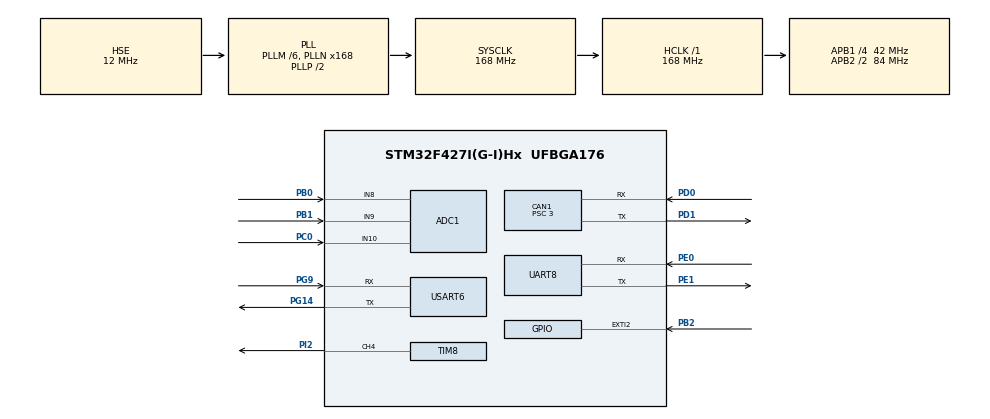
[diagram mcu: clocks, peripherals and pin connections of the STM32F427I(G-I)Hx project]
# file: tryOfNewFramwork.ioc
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ADC1.Channel-0\#ChannelRegularConversion=ADC_CHANNEL_VREFINT
ADC1.Channel-1\#ChannelRegularConversion=ADC_CHANNEL_8
ADC1.Channel-2\#ChannelRegularConversion=ADC_CHANNEL_9
ADC1.Channel-3\#ChannelRegularConversion=ADC_CHANNEL_10
ADC1.ContinuousConvMode=ENABLE
ADC1.DMAContinuousRequests=ENABLE
ADC1.NbrOfConversion=4
ADC1.NbrOfConversionFlag=1
ADC1.Rank-0\#ChannelRegularConversion=1
ADC1.Rank-1\#ChannelRegularConversion=2
ADC1.Rank-2\#ChannelRegularConversion=3
ADC1.Rank-3\#ChannelRegularConversion=4
ADC1.SamplingTime-0\#ChannelRegularConversion=ADC_SAMPLETIME_56CYCLES
ADC1.SamplingTime-1\#ChannelRegularConversion=ADC_SAMPLETIME_56CYCLES
ADC1.SamplingTime-2\#ChannelRegularConversion=ADC_SAMPLETIME_56CYCLES
ADC1.SamplingTime-3\#ChannelRegularConversion=ADC_SAMPLETIME_56CYCLES
ADC1.master=1
CAN1.BS1=CAN_BS1_9TQ
CAN1.BS2=CAN_BS2_4TQ
CAN1.CalculateTimeQuantum=71.42857142857143
CAN1.Prescaler=3
Dma.ADC1.2.Direction=DMA_PERIPH_TO_MEMORY
Dma.ADC1.2.FIFOMode=DMA_FIFOMODE_DISABLE
Dma.ADC1.2.Instance=DMA2_Stream0
Dma.ADC1.2.MemDataAlignment=DMA_MDATAALIGN_HALFWORD
Dma.ADC1.2.MemInc=DMA_MINC_ENABLE
Dma.ADC1.2.Mode=DMA_CIRCULAR
Dma.ADC1.2.PeriphDataAlignment=DMA_PDATAALIGN_HALFWORD
Dma.ADC1.2.PeriphInc=DMA_PINC_DISABLE
Dma.ADC1.2.Priority=DMA_PRIORITY_LOW
Dma.Request0=USART6_RX
Dma.Request1=USART6_TX
Dma.Request2=ADC1
Dma.Request3=UART8_RX
Dma.Request4=UART8_TX
Dma.UART8_RX.3.Direction=DMA_PERIPH_TO_MEMORY
Dma.UART8_RX.3.FIFOMode=DMA_FIFOMODE_DISABLE
Dma.UART8_RX.3.Instance=DMA1_Stream6
Dma.UART8_RX.3.MemDataAlignment=DMA_MDATAALIGN_BYTE
Dma.UART8_RX.3.MemInc=DMA_MINC_ENABLE
Dma.UART8_RX.3.Mode=DMA_NORMAL
Dma.UART8_RX.3.PeriphDataAlignment=DMA_PDATAALIGN_BYTE
Dma.UART8_RX.3.PeriphInc=DMA_PINC_DISABLE
Dma.UART8_RX.3.Priority=DMA_PRIORITY_LOW
Dma.UART8_TX.4.Direction=DMA_MEMORY_TO_PERIPH
Dma.UART8_TX.4.FIFOMode=DMA_FIFOMODE_DISABLE
Dma.UART8_TX.4.Instance=DMA1_Stream0
Dma.UART8_TX.4.MemDataAlignment=DMA_MDATAALIGN_BYTE
Dma.UART8_TX.4.MemInc=DMA_MINC_ENABLE
Dma.UART8_TX.4.Mode=DMA_NORMAL
Dma.UART8_TX.4.PeriphDataAlignment=DMA_PDATAALIGN_BYTE
Dma.UART8_TX.4.PeriphInc=DMA_PINC_DISABLE
Dma.UART8_TX.4.Priority=DMA_PRIORITY_LOW
Dma.USART6_RX.0.Direction=DMA_PERIPH_TO_MEMORY
Dma.USART6_RX.0.FIFOMode=DMA_FIFOMODE_DISABLE
Dma.USART6_RX.0.Instance=DMA2_Stream1
Dma.USART6_RX.0.MemDataAlignment=DMA_MDATAALIGN_BYTE
Dma.USART6_RX.0.MemInc=DMA_MINC_ENABLE
Dma.USART6_RX.0.Mode=DMA_NORMAL
Dma.USART6_RX.0.PeriphDataAlignment=DMA_PDATAALIGN_BYTE
Dma.USART6_RX.0.PeriphInc=DMA_PINC_DISABLE
Dma.USART6_RX.0.Priority=DMA_PRIORITY_LOW
Dma.USART6_TX.1.Direction=DMA_MEMORY_TO_PERIPH
Dma.USART6_TX.1.FIFOMode=DMA_FIFOMODE_DISABLE
Dma.USART6_TX.1.Instance=DMA2_Stream6
Dma.USART6_TX.1.MemDataAlignment=DMA_MDATAALIGN_BYTE
Dma.USART6_TX.1.MemInc=DMA_MINC_ENABLE
Dma.USART6_TX.1.Mode=DMA_NORMAL
Dma.USART6_TX.1.PeriphDataAlignment=DMA_PDATAALIGN_BYTE
Dma.USART6_TX.1.PeriphInc=DMA_PINC_DISABLE
Dma.USART6_TX.1.Priority=DMA_PRIORITY_LOW
Mcu.Family=STM32F4
Mcu.Name=STM32F427I(G-I)Hx
Mcu.Package=UFBGA176
NVIC.CAN1_RX0_IRQn=true\:0\:0\:false\:false\:true\:true\:true
NVIC.CAN1_TX_IRQn=true\:0\:0\:false\:false\:true\:true\:true
NVIC.DMA1_Stream0_IRQn=true\:0\:0\:false\:false\:true\:false\:true
NVIC.DMA1_Stream6_IRQn=true\:0\:0\:false\:false\:true\:false\:true
NVIC.DMA2_Stream0_IRQn=true\:0\:0\:false\:false\:true\:false\:true
NVIC.DMA2_Stream1_IRQn=true\:0\:0\:false\:false\:true\:false\:true
NVIC.DMA2_Stream6_IRQn=true\:0\:0\:false\:false\:true\:false\:true
NVIC.EXTI2_IRQn=true\:0\:0\:false\:false\:true\:true\:true
NVIC.PriorityGroup=NVIC_PRIORITYGROUP_4
NVIC.TIM1_UP_TIM10_IRQn=true\:0\:0\:false\:false\:true\:true\:true
NVIC.TIM6_DAC_IRQn=true\:0\:0\:false\:false\:true\:true\:true
NVIC.UART8_IRQn=true\:0\:0\:false\:false\:true\:true\:true
NVIC.USART6_IRQn=true\:0\:0\:false\:false\:true\:true\:true
PB0.Signal=ADCx_IN8
PB1.Signal=ADCx_IN9
PB2/BOOT1.Signal=GPXTI2
PC0.Signal=ADCx_IN10
PD0.Mode=Master
PD0.Signal=CAN1_RX
PD1.Mode=Master
PD1.Signal=CAN1_TX
PE0.Mode=Asynchronous
PE0.Signal=UART8_RX
PE1.Mode=Asynchronous
PE1.Signal=UART8_TX
PG14.Mode=Asynchronous
PG14.Signal=USART6_TX
PG9.Mode=Asynchronous
PG9.Signal=USART6_RX
PH0/OSC_IN.Mode=HSE-External-Oscillator
PH0/OSC_IN.Signal=RCC_OSC_IN
PH1/OSC_OUT.Mode=HSE-External-Oscillator
PH1/OSC_OUT.Signal=RCC_OSC_OUT
PI2.Signal=S_TIM8_CH4
ProjectManager.HeapSize=0x200
ProjectManager.StackSize=0x400
ProjectManager.TargetToolchain=MDK-ARM V5
RCC.48MHZClocksFreq_Value=84000000
RCC.AHBFreq_Value=168000000
RCC.APB1CLKDivider=RCC_HCLK_DIV4
RCC.APB1Freq_Value=42000000
RCC.APB1TimFreq_Value=84000000
RCC.APB2CLKDivider=RCC_HCLK_DIV2
RCC.APB2Freq_Value=84000000
RCC.APB2TimFreq_Value=168000000
RCC.CortexFreq_Value=168000000
RCC.HCLKFreq_Value=168000000
RCC.HSE_VALUE=12000000
RCC.HSI_VALUE=16000000
RCC.LSE_VALUE=32768
RCC.PLLM=6
RCC.PLLN=168
RCC.PLLSourceVirtual=RCC_PLLSOURCE_HSE
RCC.SYSCLKFreq_VALUE=168000000
RCC.SYSCLKSource=RCC_SYSCLKSOURCE_PLLCLK
RCC.VCOOutputFreq_Value=336000000
SH.ADCx_IN10.0=ADC1_IN10,IN10
SH.ADCx_IN8.0=ADC1_IN8,IN8
SH.ADCx_IN9.0=ADC1_IN9,IN9
SH.S_TIM8_CH4.0=TIM8_CH4,PWM Generation4 CH4
TIM10.Period=1000
TIM10.Prescaler=84-1
TIM6.Period=42
TIM6.Prescaler=20-1
TIM8.Channel-PWM\ Generation4\ CH4=TIM_CHANNEL_4
TIM8.Period=4200
TIM8.Prescaler=4-1
UART8.VirtualMode=Asynchronous
USART6.VirtualMode=VM_ASYNC
VP_ADC1_Vref_Input.Mode=IN-Vrefint
VP_TIM10_VS_ClockSourceINT.Mode=Enable_Timer
VP_TIM6_VS_ClockSourceINT.Mode=Enable_Timer
board=custom

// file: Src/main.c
/* USER CODE BEGIN Header */
/**
  ******************************************************************************
  * @file           : main.c
  * @brief          : Main program body
  ******************************************************************************
  * @attention
  *
  * <h2><center>&copy; Copyright (c) 2019 STMicroelectronics.
  * All rights reserved.</center></h2>
  *
  * This software component is licensed by ST under BSD 3-Clause license,
  * the "License"; You may not use this file except in compliance with the
  * License. You may obtain a copy of the License at:
  *                        opensource.org/licenses/BSD-3-Clause
  *
  ******************************************************************************
  */
	/*
	********************************************************************************
	*All the ITs are used to receive data and other procedures are done in while(1)*
	********************************************************************************
	*/
/* USER CODE END Header */

#include "main.h"
#include "adc.h"
#include "can.h"
#include "dma.h"
#include "tim.h"
#include "usart.h"
#include "gpio.h"

void SystemClock_Config(void);

/* USER CODE BEGIN 0 */
motor_receive_struct motorReceive;
motor_transmit_struct motorTransmit;
judge_receive_struct judgeReceive;
judge_transmit_struct judgeTransmit;
/* USER CODE END 0 */

int main(void)
{

  /* MCU Configuration--------------------------------------------------------*/

  /* Reset of all peripherals, Initializes the Flash interface and the Systick. */
  HAL_Init();

  /* Configure the system clock */
  SystemClock_Config();

  /* Initialize all configured peripherals */
  MX_GPIO_Init();
  MX_DMA_Init();
  MX_TIM6_Init();
  MX_CAN1_Init();
  MX_TIM8_Init();
  MX_TIM10_Init();
  MX_USART6_UART_Init();
  MX_ADC1_Init();
  MX_UART8_Init();

  /* Infinite loop */
  while (1)
  {

  }
}

void SystemClock_Config(void)
{
  RCC_OscInitTypeDef RCC_OscInitStruct = {0};
  RCC_ClkInitTypeDef RCC_ClkInitStruct = {0};

  /** Configure the main internal regulator output voltage
  */
  __HAL_RCC_PWR_CLK_ENABLE();
  __HAL_PWR_VOLTAGESCALING_CONFIG(PWR_REGULATOR_VOLTAGE_SCALE1);
  /** Initializes the CPU, AHB and APB busses clocks
  */
  RCC_OscInitStruct.OscillatorType = RCC_OSCILLATORTYPE_HSE;
  RCC_OscInitStruct.HSEState = RCC_HSE_ON;
  RCC_OscInitStruct.PLL.PLLState = RCC_PLL_ON;
  RCC_OscInitStruct.PLL.PLLSource = RCC_PLLSOURCE_HSE;
  RCC_OscInitStruct.PLL.PLLM = 6;
  RCC_OscInitStruct.PLL.PLLN = 168;
  RCC_OscInitStruct.PLL.PLLP = RCC_PLLP_DIV2;
  RCC_OscInitStruct.PLL.PLLQ = 4;
  if (HAL_RCC_OscConfig(&RCC_OscInitStruct) != HAL_OK)
  {
    Error_Handler();
  }
  /** Initializes the CPU, AHB and APB busses clocks
  */
  RCC_ClkInitStruct.ClockType = RCC_CLOCKTYPE_HCLK|RCC_CLOCKTYPE_SYSCLK
                              |RCC_CLOCKTYPE_PCLK1|RCC_CLOCKTYPE_PCLK2;
  RCC_ClkInitStruct.SYSCLKSource = RCC_SYSCLKSOURCE_PLLCLK;
  RCC_ClkInitStruct.AHBCLKDivider = RCC_SYSCLK_DIV1;
  RCC_ClkInitStruct.APB1CLKDivider = RCC_HCLK_DIV4;
  RCC_ClkInitStruct.APB2CLKDivider = RCC_HCLK_DIV2;

  if (HAL_RCC_ClockConfig(&RCC_ClkInitStruct, FLASH_LATENCY_5) != HAL_OK)
  {
    Error_Handler();
  }
}

void Error_Handler(void)
{
}

/************************ (C) COPYRIGHT STMicroelectronics *****END OF FILE****/
